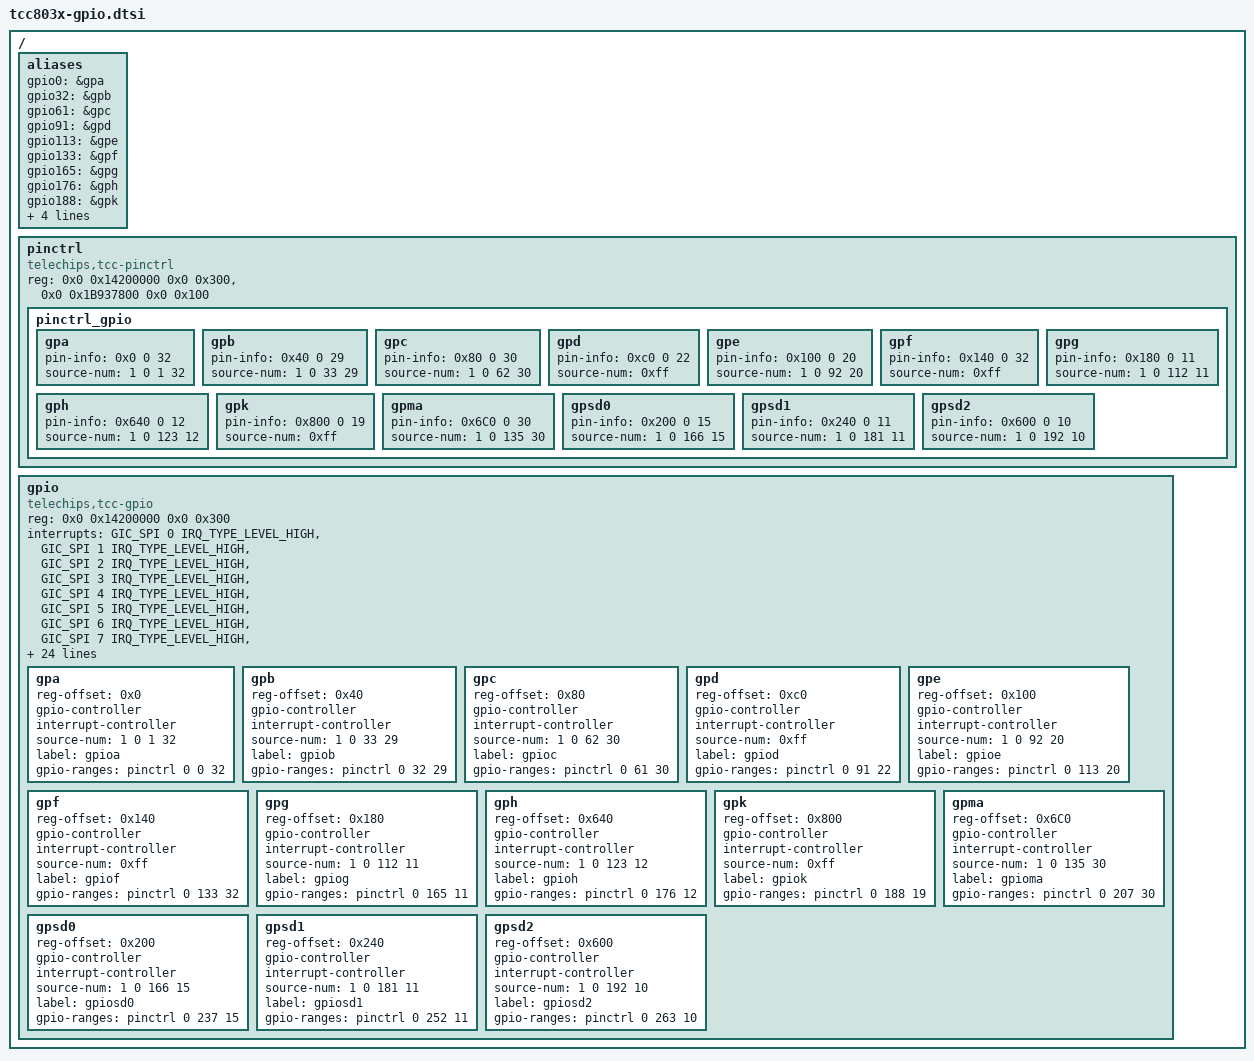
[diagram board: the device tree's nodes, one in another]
// SPDX-License-Identifier: (GPL-2.0-or-later OR MIT)
/*
 * Copyright (C) 2023 Telechips Inc.
 */

#include <dt-bindings/interrupt-controller/arm-gic.h>

/ {
	aliases {
		gpio0 = &gpa;
		gpio32 = &gpb;
		gpio61 = &gpc;
		gpio91 = &gpd;
		gpio113 = &gpe;
		gpio133 = &gpf;
		gpio165 = &gpg;
		gpio176 = &gph;
		gpio188 = &gpk;
		gpio207 = &gpma;
		gpio237 = &gpsd0;
		gpio252 = &gpsd1;
		gpio263 = &gpsd2;
	};

	pinctrl: pinctrl {
		compatible = "telechips,tcc-pinctrl";
		reg = <0x0 0x14200000 0x0 0x300>,
		      <0x0 0x1B937800 0x0 0x100>;	/* gpio, pmgpio */

		pinctrl_gpio {
			gpa {
				pin-info = <0x0 0 32>;
				source-num = <1 0 1 32>;
			};

			gpb {
				pin-info = <0x40 0 29>;
				source-num = <1 0 33 29>;
			};

			gpc {
				pin-info = <0x80 0 30>;
				source-num =  <1 0 62 30>;
			};

			gpd {
				pin-info = <0xc0 0 22>;
				source-num = <0xff>;
			};

			gpe {
				pin-info = <0x100 0 20>;
				source-num = <1 0 92 20>;
			};

			gpf {
				pin-info = <0x140 0 32>;
				source-num = <0xff>;
			};

			gpg {
				pin-info = <0x180 0 11>;
				source-num = <1 0 112 11>;
			};

			gph {
				pin-info = <0x640 0 12>;
				source-num = <1 0 123 12>;
			};

			gpk {
				pin-info = <0x800 0 19>;
				source-num = <0xff>;
			};

			gpma {
				pin-info = <0x6C0 0 30>;
				source-num = <1 0 135 30>;
			};

			gpsd0 {
				pin-info = <0x200 0 15>;
				source-num = <1 0 166 15>;
			};

			gpsd1 {
				pin-info = <0x240 0 11>;
				source-num = <1 0 181 11>;
			};

			gpsd2 {
				pin-info = <0x600 0 10>;
				source-num = <1 0 192 10>;
			};
		};
	};

	gpio: gpio {
		compatible = "telechips,tcc-gpio";
		reg = <0x0 0x14200000 0x0 0x300>;
		interrupts = <GIC_SPI 0 IRQ_TYPE_LEVEL_HIGH>,
			     <GIC_SPI 1 IRQ_TYPE_LEVEL_HIGH>,
			     <GIC_SPI 2 IRQ_TYPE_LEVEL_HIGH>,
			     <GIC_SPI 3 IRQ_TYPE_LEVEL_HIGH>,
			     <GIC_SPI 4 IRQ_TYPE_LEVEL_HIGH>,
			     <GIC_SPI 5 IRQ_TYPE_LEVEL_HIGH>,
			     <GIC_SPI 6 IRQ_TYPE_LEVEL_HIGH>,
			     <GIC_SPI 7 IRQ_TYPE_LEVEL_HIGH>,
			     <GIC_SPI 8 IRQ_TYPE_LEVEL_HIGH>,
			     <GIC_SPI 9 IRQ_TYPE_LEVEL_HIGH>,
			     <GIC_SPI 10 IRQ_TYPE_LEVEL_HIGH>,
			     <GIC_SPI 11 IRQ_TYPE_LEVEL_HIGH>,
			     <GIC_SPI 12 IRQ_TYPE_LEVEL_HIGH>,
			     <GIC_SPI 13 IRQ_TYPE_LEVEL_HIGH>,
			     <GIC_SPI 14 IRQ_TYPE_LEVEL_HIGH>,
			     <GIC_SPI 15 IRQ_TYPE_LEVEL_HIGH>,
			     <GIC_SPI 16 IRQ_TYPE_LEVEL_HIGH>,
			     <GIC_SPI 17 IRQ_TYPE_LEVEL_HIGH>,
			     <GIC_SPI 18 IRQ_TYPE_LEVEL_HIGH>,
			     <GIC_SPI 19 IRQ_TYPE_LEVEL_HIGH>,
			     <GIC_SPI 20 IRQ_TYPE_LEVEL_HIGH>,
			     <GIC_SPI 21 IRQ_TYPE_LEVEL_HIGH>,
			     <GIC_SPI 22 IRQ_TYPE_LEVEL_HIGH>,
			     <GIC_SPI 23 IRQ_TYPE_LEVEL_HIGH>,
			     <GIC_SPI 24 IRQ_TYPE_LEVEL_HIGH>,
			     <GIC_SPI 25 IRQ_TYPE_LEVEL_HIGH>,
			     <GIC_SPI 26 IRQ_TYPE_LEVEL_HIGH>,
			     <GIC_SPI 27 IRQ_TYPE_LEVEL_HIGH>,
			     <GIC_SPI 28 IRQ_TYPE_LEVEL_HIGH>,
			     <GIC_SPI 29 IRQ_TYPE_LEVEL_HIGH>,
			     <GIC_SPI 30 IRQ_TYPE_LEVEL_HIGH>,
			     <GIC_SPI 31 IRQ_TYPE_LEVEL_HIGH>;

		gpa: gpa {
			reg-offset = <0x0>;
			gpio-controller;
			#gpio-cells = <2>;
			interrupt-controller;
			#interrupt-cells = <2>;
			source-num = <1 0 1 32>;
			label = "gpioa";
			gpio-ranges = <&pinctrl 0 0 32>;
		};

		gpb: gpb {
			reg-offset = <0x40>;
			gpio-controller;
			#gpio-cells = <2>;
			interrupt-controller;
			#interrupt-cells = <2>;
			source-num = <1 0 33 29>;
			label = "gpiob";
			gpio-ranges = <&pinctrl 0 32 29>;
		};

		gpc: gpc {
			reg-offset = <0x80>;
			gpio-controller;
			#gpio-cells = <2>;
			interrupt-controller;
			#interrupt-cells = <2>;
			source-num =  <1 0 62 30>;
			label = "gpioc";
			gpio-ranges = <&pinctrl 0 61 30>;
		};

		gpd: gpd {
			reg-offset = <0xc0>;
			gpio-controller;
			#gpio-cells = <2>;
			interrupt-controller;
			#interrupt-cells = <2>;
			source-num = <0xff>;
			label = "gpiod";
			gpio-ranges = <&pinctrl 0 91 22>;
		};

		gpe: gpe {
			reg-offset = <0x100>;
			gpio-controller;
			#gpio-cells = <2>;
			interrupt-controller;
			#interrupt-cells = <2>;
			source-num = <1 0 92 20>;
			label = "gpioe";
			gpio-ranges = <&pinctrl 0 113 20>;
		};

		gpf: gpf {
			reg-offset = <0x140>;
			gpio-controller;
			#gpio-cells = <2>;
			interrupt-controller;
			#interrupt-cells = <2>;
			source-num = <0xff>;
			label = "gpiof";
			gpio-ranges = <&pinctrl 0 133 32>;
		};

		gpg: gpg {
			reg-offset = <0x180>;
			gpio-controller;
			#gpio-cells = <2>;
			interrupt-controller;
			#interrupt-cells = <2>;
			source-num = <1 0 112 11>;
			label = "gpiog";
			gpio-ranges = <&pinctrl 0 165 11>;
		};

		gph: gph {
			reg-offset = <0x640>;
			gpio-controller;
			#gpio-cells = <2>;
			interrupt-controller;
			#interrupt-cells = <2>;
			source-num = <1 0 123 12>;
			label = "gpioh";
			gpio-ranges = <&pinctrl 0 176 12>;
		};

		gpk: gpk {
			reg-offset = <0x800>;
			gpio-controller;
			#gpio-cells = <2>;
			interrupt-controller;
			#interrupt-cells = <2>;
			source-num = <0xff>;
			label = "gpiok";
			gpio-ranges = <&pinctrl 0 188 19>;
		};

		gpma: gpma {
			reg-offset = <0x6C0>;
			gpio-controller;
			#gpio-cells = <2>;
			interrupt-controller;
			#interrupt-cells = <2>;
			source-num = <1 0 135 30>;
			label = "gpioma";
			gpio-ranges = <&pinctrl 0 207 30>;
		};

		gpsd0: gpsd0 {
			reg-offset = <0x200>;
			gpio-controller;
			#gpio-cells = <2>;
			interrupt-controller;
			#interrupt-cells = <2>;
			source-num = <1 0 166 15>;
			label = "gpiosd0";
			gpio-ranges = <&pinctrl 0 237 15>;
		};

		gpsd1: gpsd1 {
			reg-offset = <0x240>;
			gpio-controller;
			#gpio-cells = <2>;
			interrupt-controller;
			#interrupt-cells = <2>;
			source-num = <1 0 181 11>;
			label = "gpiosd1";
			gpio-ranges = <&pinctrl 0 252 11>;
		};

		gpsd2: gpsd2 {
			reg-offset = <0x600>;
			gpio-controller;
			#gpio-cells = <2>;
			interrupt-controller;
			#interrupt-cells = <2>;
			source-num = <1 0 192 10>;
			label = "gpiosd2";
			gpio-ranges = <&pinctrl 0 263 10>;
		};
	};
};
